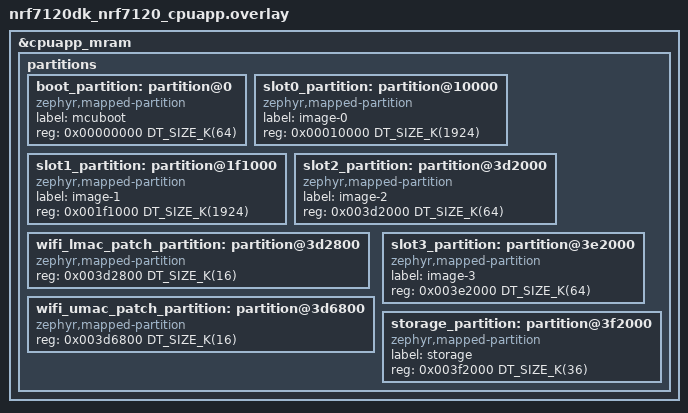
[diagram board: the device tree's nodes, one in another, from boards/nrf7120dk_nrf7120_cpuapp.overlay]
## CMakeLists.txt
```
#
# Copyright (c) 2026 Nordic Semiconductor ASA
#
# SPDX-License-Identifier: LicenseRef-Nordic-5-Clause
#

cmake_minimum_required(VERSION 3.20.0)

find_package(Zephyr REQUIRED HINTS $ENV{ZEPHYR_BASE})
project(wifi_patch_dfu)

target_sources(app PRIVATE src/main.c)
```

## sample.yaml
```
sample:
  name: nRF7120 Wi-Fi patch DFU
  description: >
    Proof of concept: update the Wi-Fi LMAC/UMAC ROM patches as a separate
    MCUboot image (image 1) via serial DFU, independently of the application.
common:
  sysbuild: true
  platform_allow:
    - nrf7120dk/nrf7120/cpuapp
  build_only: true
tests:
  sample.dfu.wifi_patch_dfu:
    tags:
      - dfu
      - ci_samples_dfu
    integration_platforms:
      - nrf7120dk/nrf7120/cpuapp
```

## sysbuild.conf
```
# MCUboot as the single-stage bootloader (NOT two-stage NSIB+MCUboot): this is
# what makes MCUboot map slot2/slot3 to image 1.
SB_CONFIG_BOOTLOADER_MCUBOOT=y
SB_CONFIG_SECURE_BOOT_APPCORE=n

# Two updateable images: image 0 (app) + image 1 (Wi-Fi patch). This forwards
# CONFIG_UPDATEABLE_IMAGE_NUMBER=2 to both MCUboot and the application.
SB_CONFIG_MCUBOOT_UPDATEABLE_IMAGES=2

# The Wi-Fi patch is registered as one extra (non-Zephyr) signed image.
SB_CONFIG_MCUBOOT_EXTRA_IMAGES=1

# Produce DFU artifacts that include image 1.
SB_CONFIG_DFU_MULTI_IMAGE_PACKAGE_BUILD=y
SB_CONFIG_DFU_MULTI_IMAGE_PACKAGE_APP=y
SB_CONFIG_DFU_ZIP=y
```

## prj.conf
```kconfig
# Build an MCUboot-signed application (image 0).
CONFIG_BOOTLOADER_MCUBOOT=y

# Two updateable images: app (0) + Wi-Fi patch (1). Must match
# SB_CONFIG_MCUBOOT_UPDATEABLE_IMAGES in sysbuild.conf.
CONFIG_UPDATEABLE_IMAGE_NUMBER=2

# Flash access + MCUboot image management (read headers, confirm image 1).
CONFIG_FLASH=y
CONFIG_FLASH_MAP=y
CONFIG_STREAM_FLASH=y
CONFIG_IMG_MANAGER=y
CONFIG_REBOOT=y

# MCUmgr / SMP over UART so a new patch image can be uploaded without a debugger.
CONFIG_NET_BUF=y
CONFIG_ZCBOR=y
CONFIG_CRC=y
CONFIG_BASE64=y
CONFIG_MCUMGR=y
CONFIG_UART_MCUMGR=y
CONFIG_MCUMGR_TRANSPORT_UART=y
CONFIG_MCUMGR_GRP_IMG=y
CONFIG_MCUMGR_GRP_OS=y

# img_mgmt must expose image 1 (slots 2/3). 2 images needs a >=512B net buf.
CONFIG_MCUMGR_GRP_IMG_UPDATABLE_IMAGE_NUMBER=2
CONFIG_MCUMGR_TRANSPORT_NETBUF_SIZE=512

# Command handlers need a larger stack.
CONFIG_SYSTEM_WORKQUEUE_STACK_SIZE=2304
CONFIG_MAIN_STACK_SIZE=2176

# Console + logging.
CONFIG_CONSOLE=y
CONFIG_LOG=y
CONFIG_MCUBOOT_UTIL_LOG_LEVEL_WRN=y
CONFIG_LOG_MAX_LEVEL=3
```

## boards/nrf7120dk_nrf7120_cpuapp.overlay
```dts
/*
 * Copyright (c) 2026 Nordic Semiconductor ASA
 *
 * SPDX-License-Identifier: LicenseRef-Nordic-5-Clause
 */

/*
 * Two-image MCUboot layout for the Wi-Fi patch DFU PoC.
 *
 *   image 0 (application)  : slot0_partition (primary) / slot1_partition (secondary)
 *   image 1 (Wi-Fi patch)  : slot2_partition (primary) / slot3_partition (secondary)
 *
 * MCUboot maps slotN_partition -> image (N/2), slot (N%2). It validates and
 * swaps image 1 but never boots it; the application calls into it.
 *
 * The image-1 primary slot holds one signed blob that internally carries two
 * sub-applications (LMAC, UMAC) at 4 KiB-aligned origins, mirroring the
 * proposed nRF7120 Wi-Fi patch architecture:
 *
 *   slot2 base 0x3D2000
 *     + 0x0800  MCUboot header (CONFIG_ROM_START_OFFSET on nRF7120)
 *     0x3D2800  LMAC sub-application  (wifi_lmac_patch_partition)
 *     0x3D6800  UMAC sub-application  (wifi_umac_patch_partition)
 *
 * The LMAC/UMAC nodes overlap slot2 by design (they describe regions inside the
 * patch image); the app reads their base via DT_REG_ADDR to locate each entry.
 */

&cpuapp_mram {
	/delete-node/ partitions;

	partitions {
		ranges;
		#address-cells = <1>;
		#size-cells = <1>;

		boot_partition: partition@0 {
			compatible = "zephyr,mapped-partition";
			label = "mcuboot";
			reg = <0x00000000 DT_SIZE_K(64)>;
		};

		slot0_partition: partition@10000 {
			compatible = "zephyr,mapped-partition";
			label = "image-0";
			reg = <0x00010000 DT_SIZE_K(1924)>;
		};

		slot1_partition: partition@1f1000 {
			compatible = "zephyr,mapped-partition";
			label = "image-1";
			reg = <0x001f1000 DT_SIZE_K(1924)>;
		};

		slot2_partition: partition@3d2000 {
			compatible = "zephyr,mapped-partition";
			label = "image-2";
			reg = <0x003d2000 DT_SIZE_K(64)>;
		};

		wifi_lmac_patch_partition: partition@3d2800 {
			compatible = "zephyr,mapped-partition";
			reg = <0x003d2800 DT_SIZE_K(16)>;
		};

		wifi_umac_patch_partition: partition@3d6800 {
			compatible = "zephyr,mapped-partition";
			reg = <0x003d6800 DT_SIZE_K(16)>;
		};

		slot3_partition: partition@3e2000 {
			compatible = "zephyr,mapped-partition";
			label = "image-3";
			reg = <0x003e2000 DT_SIZE_K(64)>;
		};

		storage_partition: partition@3f2000 {
			compatible = "zephyr,mapped-partition";
			label = "storage";
			reg = <0x003f2000 DT_SIZE_K(36)>;
		};
	};
};
```

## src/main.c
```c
/*
 * Copyright (c) 2026 Nordic Semiconductor ASA
 *
 * SPDX-License-Identifier: LicenseRef-Nordic-5-Clause
 */

/*
 * nRF7120 Wi-Fi patch DFU PoC - application (MCUboot image 0).
 *
 * The Wi-Fi patch is a separate, MCUboot-signed image 1 (slot2/slot3) that
 * MCUboot validates and swaps but never boots. This application:
 *   1. reads the patch image's MCUboot header (proves the on-flash image),
 *   2. calls the LMAC and UMAC entry functions at their fixed origins
 *      (proves the patch *code* runs), printing the version each returns,
 *   3. confirms image 1 so MCUboot keeps it after a test-swap.
 *
 * Update the patch over UART (no debugger) with mcumgr:
 *   mcumgr ... image upload -n 1 wifi_patch.signed.bin
 *   mcumgr ... image test <hash> ; mcumgr ... reset
 * After reboot the printed version changes -> the patch was updated via MCUboot.
 */

#include <zephyr/kernel.h>
#include <zephyr/sys/printk.h>
#include <zephyr/devicetree.h>
#include <zephyr/storage/flash_map.h>
#include <zephyr/dfu/mcuboot.h>

/* image 1 primary slot and the two sub-application origins (from the overlay). */
#define PATCH_SLOT_ID	FIXED_PARTITION_ID(slot2_partition)
#define LMAC_ENTRY_ADDR	((uint32_t)DT_REG_ADDR(DT_NODELABEL(wifi_lmac_patch_partition)))
#define UMAC_ENTRY_ADDR	((uint32_t)DT_REG_ADDR(DT_NODELABEL(wifi_umac_patch_partition)))

/* ABI contract with the patch blob (see wifi_patch/patch.c). */
struct patch_info {
	uint32_t version;
	const char *msg;
};

typedef const struct patch_info *(*patch_entry_fn_t)(void);

static void call_patch(const char *core, uint32_t addr)
{
	/* OR 1: Cortex-M is Thumb-only; the call target must have bit 0 set. */
	patch_entry_fn_t entry = (patch_entry_fn_t)(addr | 1u);
	const struct patch_info *pi = entry();

	printk("%s entry @ 0x%08x -> Version Info: %u (%s)\n",
	       core, addr, pi->version, pi->msg);
}

int main(void)
{
	struct mcuboot_img_header mh;
	int rc;

	printk("\n*** nRF7120 Wi-Fi patch DFU PoC (app built %s %s) ***\n",
	       __DATE__, __TIME__);

	/* (1) MCUboot header of the patch image: validates it and gives the
	 * version (the "on-flash image" proof). A non-zero rc means there is no
	 * valid signed patch in the slot, so do not jump into it.
	 */
	rc = boot_read_bank_header(PATCH_SLOT_ID, &mh, sizeof(mh));
	if (rc != 0 || mh.mcuboot_version != 1) {
		printk("Patch image not present/valid (rc %d); skipping patch calls\n", rc);
		return 0;
	}
	printk("Patch image (image 1) MCUboot version: %u.%u.%u+%u, size %u\n",
	       mh.h.v1.sem_ver.major, mh.h.v1.sem_ver.minor,
	       mh.h.v1.sem_ver.revision, mh.h.v1.sem_ver.build_num,
	       mh.h.v1.image_size);

	/* (2) Run the patch code and show the versions it reports. */
	call_patch("LMAC", LMAC_ENTRY_ADDR);
	call_patch("UMAC", UMAC_ENTRY_ADDR);

	/* (3) Keep image 1 after a test-swap so the update sticks. */
	rc = boot_write_img_confirmed_multi(1);
	printk("Confirm image 1: %s (rc %d)\n", rc == 0 ? "ok" : "skipped", rc);

	printk("Ready. Upload a new patch over UART: mcumgr ... image upload -n 1 <bin>\n");
	return 0;
}
```
